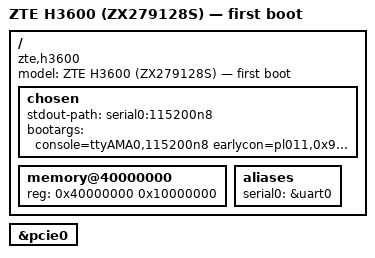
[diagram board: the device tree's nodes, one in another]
// SPDX-License-Identifier: GPL-2.0
/*
 * ZTE H3600 (DIGI Spain) — ZX279128S SoC
 * 256 MiB DDR @ 0x40000000, 128 MiB ESMT SPI NAND
 */

/dts-v1/;

#include "zx279128s.dtsi"

/ {
	model = "ZTE H3600 (ZX279128S) — first boot";
	compatible = "zte,h3600", "zte,zx279128s";

	chosen {
		stdout-path = "serial0:115200n8";
		bootargs = "console=ttyAMA0,115200n8 earlycon=pl011,0x94404000 earlyprintk keep_bootcon ignore_loglevel";
	};

	memory@40000000 {
		device_type = "memory";
		reg = <0x40000000 0x10000000>;	/* 256 MiB */
	};

	aliases {
		serial0 = &uart0;
	};
};

&pcie0 {
	/* MT7915 WiFi 6 chip is wired to PCIe port 0 in this board */
	status = "okay";
};

/* Mainline-style `eth` removed from stockport DTSI — using stock_{pon,npp,
 * tm,pp,idm,gephy} nodes instead so stock plat-zxylzb_9128S.ko's
 * of_find_matching_node_and_match() can find them. */
